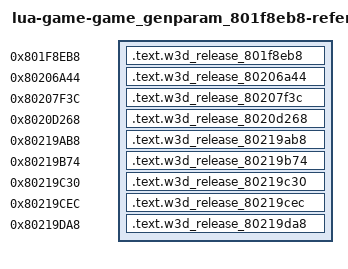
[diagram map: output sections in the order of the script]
/* Generated reference-only placements. All bodies are source-built. */
OUTPUT_FORMAT("elf32-powerpc")
OUTPUT_ARCH(powerpc)
ENTRY(w3d_release_801f8eb8)
_SDA_BASE_ = 0x804b2540;
_SDA2_BASE_ = 0x804c2540;
fn_801f8fbc = 0x801f8fbc;
fn_80206b40 = 0x80206b40;
fn_8020803c = 0x8020803c;
fn_8020d36c = 0x8020d36c;
fn_80219edc = 0x80219edc;
fn_80219fc8 = 0x80219fc8;
fn_8021a0b4 = 0x8021a0b4;
fn_8021a11c = 0x8021a11c;
fn_8021a208 = 0x8021a208;
SECTIONS {
  .text.w3d_release_801f8eb8 0x801f8eb8 : { *(.text.w3d_release_801f8eb8) }
  .text.w3d_release_80206a44 0x80206a44 : { *(.text.w3d_release_80206a44) }
  .text.w3d_release_80207f3c 0x80207f3c : { *(.text.w3d_release_80207f3c) }
  .text.w3d_release_8020d268 0x8020d268 : { *(.text.w3d_release_8020d268) }
  .text.w3d_release_80219ab8 0x80219ab8 : { *(.text.w3d_release_80219ab8) }
  .text.w3d_release_80219b74 0x80219b74 : { *(.text.w3d_release_80219b74) }
  .text.w3d_release_80219c30 0x80219c30 : { *(.text.w3d_release_80219c30) }
  .text.w3d_release_80219cec 0x80219cec : { *(.text.w3d_release_80219cec) }
  .text.w3d_release_80219da8 0x80219da8 : { *(.text.w3d_release_80219da8) }
  /DISCARD/ : { *(.text*) *(.rodata*) *(.data*) *(.bss*) *(.sdata*) *(.sbss*) *(.comment) }
}
